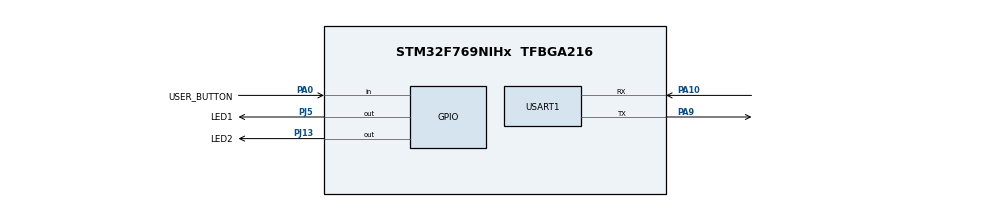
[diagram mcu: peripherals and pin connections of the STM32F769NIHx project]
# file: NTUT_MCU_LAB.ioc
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ADC1.Channel-0\#ChannelRegularConversion=ADC_CHANNEL_TEMPSENSOR
ADC1.NbrOfConversion=1
ADC1.NbrOfConversionFlag=1
ADC1.Rank-0\#ChannelRegularConversion=1
ADC1.SamplingTime-0\#ChannelRegularConversion=ADC_SAMPLETIME_3CYCLES
ADC1.master=1
Mcu.Family=STM32F7
Mcu.Name=STM32F769NIHx
Mcu.Package=TFBGA216
NVIC.PriorityGroup=NVIC_PRIORITYGROUP_4
NVIC.TIM1_UP_TIM10_IRQn=true\:0\:0\:false\:false\:true\:true\:true\:true
NVIC.TIM6_DAC_IRQn=true\:0\:0\:false\:false\:true\:true\:true\:true
PA0/WKUP.GPIO_Label=USER_BUTTON
PA0/WKUP.Signal=GPIO_Input
PA10.Mode=Asynchronous
PA10.Signal=USART1_RX
PA9.Mode=Asynchronous
PA9.Signal=USART1_TX
PJ13.GPIO_Label=LED2
PJ13.Signal=GPIO_Output
PJ5.GPIO_Label=LED1
PJ5.PinState=GPIO_PIN_SET
PJ5.Signal=GPIO_Output
ProjectManager.HeapSize=0x200
ProjectManager.StackSize=0x400
ProjectManager.TargetToolchain=STM32CubeIDE
RCC.HSE_VALUE=25000000
RCC.HSI_VALUE=16000000
RCC.LSE_VALUE=32768
RCC.USBFreq_Value=96000000
RCC.VCOOutputFreq_Value=192000000
TIM1.Period=999
TIM1.Prescaler=15999
TIM6.Prescaler=159
USART1.VirtualMode-Asynchronous=VM_ASYNC
VP_ADC1_TempSens_Input.Mode=IN-TempSens
VP_TIM1_VS_ClockSourceINT.Mode=Internal
VP_TIM6_VS_ClockSourceINT.Mode=Enable_Timer
board=custom

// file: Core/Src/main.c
/* USER CODE BEGIN Header */
/**
  ******************************************************************************
  * @file           : main.c
  * @brief          : Main program body
  ******************************************************************************
  * @attention
  *
  * Copyright (c) 2026 STMicroelectronics.
  * All rights reserved.
  *
  * This software is licensed under terms that can be found in the LICENSE file
  * in the root directory of this software component.
  * If no LICENSE file comes with this software, it is provided AS-IS.
  *
  ******************************************************************************
  */
/* USER CODE END Header */
#include "main.h"

/* USER CODE BEGIN Includes */
#include "lab01_gpio.h"
#include "lab02_uart.h"
#include "lab03_uart2.h"
#include "lab04_adc.h"
#include "lab05_timer.h"
/* USER CODE END Includes */

ADC_HandleTypeDef hadc1;

TIM_HandleTypeDef htim1;
TIM_HandleTypeDef htim6;

UART_HandleTypeDef huart1;

void SystemClock_Config(void);
static void MX_GPIO_Init(void);
static void MX_USART1_UART_Init(void);
static void MX_ADC1_Init(void);
static void MX_TIM1_Init(void);
static void MX_TIM6_Init(void);

int main(void)
{

  /* MCU Configuration--------------------------------------------------------*/

  /* Reset of all peripherals, Initializes the Flash interface and the Systick. */
  HAL_Init();

  /* Configure the system clock */
  SystemClock_Config();

  /* Initialize all configured peripherals */
  MX_GPIO_Init();
  MX_USART1_UART_Init();
  MX_ADC1_Init();
  MX_TIM1_Init();
  MX_TIM6_Init();
  /* USER CODE BEGIN 2 */
  LAB5_3_B();
  /* USER CODE END 2 */

  /* Infinite loop */
  while (1)
  {

  }
}

void SystemClock_Config(void)
{
  RCC_OscInitTypeDef RCC_OscInitStruct = {0};
  RCC_ClkInitTypeDef RCC_ClkInitStruct = {0};

  /** Configure the main internal regulator output voltage
  */
  __HAL_RCC_PWR_CLK_ENABLE();
  __HAL_PWR_VOLTAGESCALING_CONFIG(PWR_REGULATOR_VOLTAGE_SCALE3);

  /** Initializes the RCC Oscillators according to the specified parameters
  * in the RCC_OscInitTypeDef structure.
  */
  RCC_OscInitStruct.OscillatorType = RCC_OSCILLATORTYPE_HSI;
  RCC_OscInitStruct.HSIState = RCC_HSI_ON;
  RCC_OscInitStruct.HSICalibrationValue = RCC_HSICALIBRATION_DEFAULT;
  RCC_OscInitStruct.PLL.PLLState = RCC_PLL_NONE;
  if (HAL_RCC_OscConfig(&RCC_OscInitStruct) != HAL_OK)
  {
    Error_Handler();
  }

  /** Initializes the CPU, AHB and APB buses clocks
  */
  RCC_ClkInitStruct.ClockType = RCC_CLOCKTYPE_HCLK|RCC_CLOCKTYPE_SYSCLK
                              |RCC_CLOCKTYPE_PCLK1|RCC_CLOCKTYPE_PCLK2;
  RCC_ClkInitStruct.SYSCLKSource = RCC_SYSCLKSOURCE_HSI;
  RCC_ClkInitStruct.AHBCLKDivider = RCC_SYSCLK_DIV1;
  RCC_ClkInitStruct.APB1CLKDivider = RCC_HCLK_DIV1;
  RCC_ClkInitStruct.APB2CLKDivider = RCC_HCLK_DIV1;

  if (HAL_RCC_ClockConfig(&RCC_ClkInitStruct, FLASH_LATENCY_0) != HAL_OK)
  {
    Error_Handler();
  }
}

static void MX_ADC1_Init(void)
{

  ADC_ChannelConfTypeDef sConfig = {0};

  /** Configure the global features of the ADC (Clock, Resolution, Data Alignment and number of conversion)
  */
  hadc1.Instance = ADC1;
  hadc1.Init.ClockPrescaler = ADC_CLOCK_SYNC_PCLK_DIV2;
  hadc1.Init.Resolution = ADC_RESOLUTION_12B;
  hadc1.Init.ScanConvMode = ADC_SCAN_DISABLE;
  hadc1.Init.ContinuousConvMode = DISABLE;
  hadc1.Init.DiscontinuousConvMode = DISABLE;
  hadc1.Init.ExternalTrigConvEdge = ADC_EXTERNALTRIGCONVEDGE_NONE;
  hadc1.Init.ExternalTrigConv = ADC_SOFTWARE_START;
  hadc1.Init.DataAlign = ADC_DATAALIGN_RIGHT;
  hadc1.Init.NbrOfConversion = 1;
  hadc1.Init.DMAContinuousRequests = DISABLE;
  hadc1.Init.EOCSelection = ADC_EOC_SINGLE_CONV;
  if (HAL_ADC_Init(&hadc1) != HAL_OK)
  {
    Error_Handler();
  }

  /** Configure for the selected ADC regular channel its corresponding rank in the sequencer and its sample time.
  */
  sConfig.Channel = ADC_CHANNEL_TEMPSENSOR;
  sConfig.Rank = ADC_REGULAR_RANK_1;
  sConfig.SamplingTime = ADC_SAMPLETIME_3CYCLES;
  if (HAL_ADC_ConfigChannel(&hadc1, &sConfig) != HAL_OK)
  {
    Error_Handler();
  }

}

static void MX_TIM1_Init(void)
{

  TIM_ClockConfigTypeDef sClockSourceConfig = {0};
  TIM_MasterConfigTypeDef sMasterConfig = {0};

  htim1.Instance = TIM1;
  htim1.Init.Prescaler = 15999;
  htim1.Init.CounterMode = TIM_COUNTERMODE_UP;
  htim1.Init.Period = 999;
  htim1.Init.ClockDivision = TIM_CLOCKDIVISION_DIV1;
  htim1.Init.RepetitionCounter = 0;
  htim1.Init.AutoReloadPreload = TIM_AUTORELOAD_PRELOAD_DISABLE;
  if (HAL_TIM_Base_Init(&htim1) != HAL_OK)
  {
    Error_Handler();
  }
  sClockSourceConfig.ClockSource = TIM_CLOCKSOURCE_INTERNAL;
  if (HAL_TIM_ConfigClockSource(&htim1, &sClockSourceConfig) != HAL_OK)
  {
    Error_Handler();
  }
  sMasterConfig.MasterOutputTrigger = TIM_TRGO_RESET;
  sMasterConfig.MasterOutputTrigger2 = TIM_TRGO2_RESET;
  sMasterConfig.MasterSlaveMode = TIM_MASTERSLAVEMODE_DISABLE;
  if (HAL_TIMEx_MasterConfigSynchronization(&htim1, &sMasterConfig) != HAL_OK)
  {
    Error_Handler();
  }

}

static void MX_TIM6_Init(void)
{

  TIM_MasterConfigTypeDef sMasterConfig = {0};

  htim6.Instance = TIM6;
  htim6.Init.Prescaler = 159;
  htim6.Init.CounterMode = TIM_COUNTERMODE_UP;
  htim6.Init.Period = 65535;
  htim6.Init.AutoReloadPreload = TIM_AUTORELOAD_PRELOAD_DISABLE;
  if (HAL_TIM_Base_Init(&htim6) != HAL_OK)
  {
    Error_Handler();
  }
  sMasterConfig.MasterOutputTrigger = TIM_TRGO_RESET;
  sMasterConfig.MasterSlaveMode = TIM_MASTERSLAVEMODE_DISABLE;
  if (HAL_TIMEx_MasterConfigSynchronization(&htim6, &sMasterConfig) != HAL_OK)
  {
    Error_Handler();
  }

}

static void MX_USART1_UART_Init(void)
{

  huart1.Instance = USART1;
  huart1.Init.BaudRate = 115200;
  huart1.Init.WordLength = UART_WORDLENGTH_8B;
  huart1.Init.StopBits = UART_STOPBITS_1;
  huart1.Init.Parity = UART_PARITY_NONE;
  huart1.Init.Mode = UART_MODE_TX_RX;
  huart1.Init.HwFlowCtl = UART_HWCONTROL_NONE;
  huart1.Init.OverSampling = UART_OVERSAMPLING_16;
  huart1.Init.OneBitSampling = UART_ONE_BIT_SAMPLE_DISABLE;
  huart1.AdvancedInit.AdvFeatureInit = UART_ADVFEATURE_NO_INIT;
  if (HAL_UART_Init(&huart1) != HAL_OK)
  {
    Error_Handler();
  }

}

static void MX_GPIO_Init(void)
{
  GPIO_InitTypeDef GPIO_InitStruct = {0};

  /* GPIO Ports Clock Enable */
  __HAL_RCC_GPIOJ_CLK_ENABLE();
  __HAL_RCC_GPIOA_CLK_ENABLE();

  /*Configure GPIO pin Output Level */
  HAL_GPIO_WritePin(LED2_GPIO_Port, LED2_Pin, GPIO_PIN_RESET);

  /*Configure GPIO pin Output Level */
  HAL_GPIO_WritePin(LED1_GPIO_Port, LED1_Pin, GPIO_PIN_SET);

  /*Configure GPIO pins : LED2_Pin LED1_Pin */
  GPIO_InitStruct.Pin = LED2_Pin|LED1_Pin;
  GPIO_InitStruct.Mode = GPIO_MODE_OUTPUT_PP;
  GPIO_InitStruct.Pull = GPIO_NOPULL;
  GPIO_InitStruct.Speed = GPIO_SPEED_FREQ_LOW;
  HAL_GPIO_Init(GPIOJ, &GPIO_InitStruct);

  /*Configure GPIO pin : USER_BUTTON_Pin */
  GPIO_InitStruct.Pin = USER_BUTTON_Pin;
  GPIO_InitStruct.Mode = GPIO_MODE_INPUT;
  GPIO_InitStruct.Pull = GPIO_NOPULL;
  HAL_GPIO_Init(USER_BUTTON_GPIO_Port, &GPIO_InitStruct);

}

void Error_Handler(void)
{
  __disable_irq();
  while (1)
  {
  }
}
